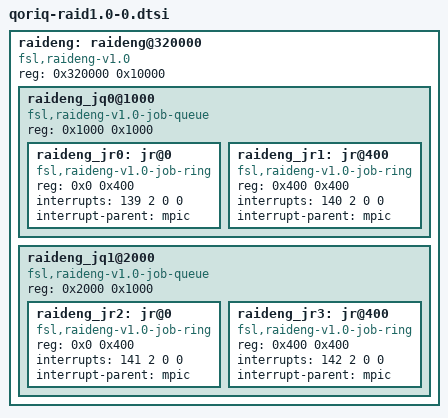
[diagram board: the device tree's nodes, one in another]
/*
 * QorIQ RAID 1.0 device tree stub [ controller @ offset 0x320000 ]
 *
 * Copyright 2012 Freescale Semiconductor Inc.
 *
 * Redistribution and use in source and binary forms, with or without
 * modification, are permitted provided that the following conditions are met:
 *     * Redistributions of source code must retain the above copyright
 *       notice, this list of conditions and the following disclaimer.
 *     * Redistributions in binary form must reproduce the above copyright
 *       notice, this list of conditions and the following disclaimer in the
 *       documentation and/or other materials provided with the distribution.
 *     * Neither the name of Freescale Semiconductor nor the
 *       names of its contributors may be used to endorse or promote products
 *       derived from this software without specific prior written permission.
 *
 *
 * ALTERNATIVELY, this software may be distributed under the terms of the
 * GNU General Public License ("GPL") as published by the Free Software
 * Foundation, either version 2 of that License or (at your option) any
 * later version.
 *
 * THIS SOFTWARE IS PROVIDED BY Freescale Semiconductor ``AS IS'' AND ANY
 * EXPRESS OR IMPLIED WARRANTIES, INCLUDING, BUT NOT LIMITED TO, THE IMPLIED
 * WARRANTIES OF MERCHANTABILITY AND FITNESS FOR A PARTICULAR PURPOSE ARE
 * DISCLAIMED. IN NO EVENT SHALL Freescale Semiconductor BE LIABLE FOR ANY
 * DIRECT, INDIRECT, INCIDENTAL, SPECIAL, EXEMPLARY, OR CONSEQUENTIAL DAMAGES
 * (INCLUDING, BUT NOT LIMITED TO, PROCUREMENT OF SUBSTITUTE GOODS OR SERVICES;
 * LOSS OF USE, DATA, OR PROFITS; OR BUSINESS INTERRUPTION) HOWEVER CAUSED AND
 * ON ANY THEORY OF LIABILITY, WHETHER IN CONTRACT, STRICT LIABILITY, OR TORT
 * (INCLUDING NEGLIGENCE OR OTHERWISE) ARISING IN ANY WAY OUT OF THE USE OF THIS
 * SOFTWARE, EVEN IF ADVISED OF THE POSSIBILITY OF SUCH DAMAGE.
 */

raideng: raideng@320000 {
	compatible = "fsl,raideng-v1.0";
	#address-cells = <1>;
	#size-cells = <1>;
	reg = <0x320000 0x10000>;
	ranges = <0 0x320000 0x10000>;

	raideng_jq0@1000 {
		compatible = "fsl,raideng-v1.0-job-queue";
		#address-cells = <1>;
		#size-cells = <1>;
		reg = <0x1000 0x1000>;
		ranges = <0x0 0x1000 0x1000>;

		raideng_jr0: jr@0 {
			compatible = "fsl,raideng-v1.0-job-ring", "fsl,raideng-v1.0-hp-ring";
			reg = <0x0 0x400>;
			interrupts = <139 2 0 0>;
			interrupt-parent = <&mpic>;
		};

		raideng_jr1: jr@400 {
			compatible = "fsl,raideng-v1.0-job-ring", "fsl,raideng-v1.0-lp-ring";
			reg = <0x400 0x400>;
			interrupts = <140 2 0 0>;
			interrupt-parent = <&mpic>;
		};
	};

	raideng_jq1@2000 {
		compatible = "fsl,raideng-v1.0-job-queue";
		#address-cells = <1>;
		#size-cells = <1>;
		reg = <0x2000 0x1000>;
		ranges = <0x0 0x2000 0x1000>;

		raideng_jr2: jr@0 {
			compatible = "fsl,raideng-v1.0-job-ring", "fsl,raideng-v1.0-hp-ring";
			reg = <0x0 0x400>;
			interrupts = <141 2 0 0>;
			interrupt-parent = <&mpic>;
		};

		raideng_jr3: jr@400 {
			compatible = "fsl,raideng-v1.0-job-ring", "fsl,raideng-v1.0-lp-ring";
			reg = <0x400 0x400>;
			interrupts = <142 2 0 0>;
			interrupt-parent = <&mpic>;
		};
	};
};
